AUTOSAR XML (schema 3.1.2)
package /Components/SWC_AdvMaxT
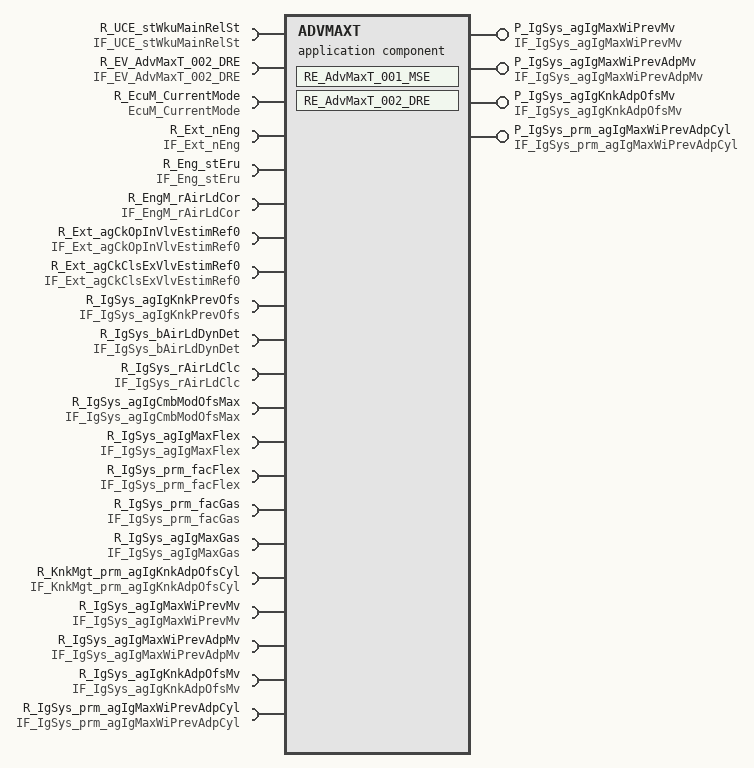
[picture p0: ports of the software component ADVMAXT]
  application software component type ADVMAXT  # AdvMaxT
    require port R_UCE_stWkuMainRelSt: required-interface=IF_UCE_stWkuMainRelSt
    4 x provide port:
      P_IgSys_agIgMaxWiPrevMv: unqueued-sender-com-spec{data-element=IgSys_agIgMaxWiPrevMv, can-invalidate=false, init-value=UInt8InitValue}, provided-interface=IF_IgSys_agIgMaxWiPrevMv
      P_IgSys_agIgMaxWiPrevAdpMv: unqueued-sender-com-spec{data-element=IgSys_agIgMaxWiPrevAdpMv, can-invalidate=false, init-value=ConstantValue}, provided-interface=IF_IgSys_agIgMaxWiPrevAdpMv
      P_IgSys_agIgKnkAdpOfsMv: unqueued-sender-com-spec{data-element=IgSys_agIgKnkAdpOfsMv, can-invalidate=false, init-value=UInt8InitValue1}, provided-interface=IF_IgSys_agIgKnkAdpOfsMv
      P_IgSys_prm_agIgMaxWiPrevAdpCyl: unqueued-sender-com-spec{data-element=IgSys_prm_agIgMaxWiPrevAdpCyl, can-invalidate=false, init-value=ArrayConstantValue}, provided-interface=IF_IgSys_prm_agIgMaxWiPrevAdpCyl
    20 x require port:
      R_EV_AdvMaxT_002_DRE: unqueued-receiver-com-spec{data-element=EV_AdvMaxT_002_DRE, init-value=UInt8InitValue3, resync-time=0}, required-interface=IF_EV_AdvMaxT_002_DRE
      R_EcuM_CurrentMode: required-interface=EcuM_CurrentMode
      R_Ext_nEng: unqueued-receiver-com-spec{data-element=Ext_nEng, init-value=ConstantValue5, resync-time=0}, required-interface=IF_Ext_nEng
      R_Eng_stEru: unqueued-receiver-com-spec{data-element=Eng_stEru, init-value=UInt8InitValue7, resync-time=0}, required-interface=IF_Eng_stEru
      R_EngM_rAirLdCor: unqueued-receiver-com-spec{data-element=EngM_rAirLdCor, init-value=ConstantValue9, resync-time=0}, required-interface=IF_EngM_rAirLdCor
      R_Ext_agCkOpInVlvEstimRef0: unqueued-receiver-com-spec{data-element=Ext_agCkOpInVlvEstimRef0, init-value=SInt16InitValue, resync-time=0}, required-interface=IF_Ext_agCkOpInVlvEstimRef0
      R_Ext_agCkClsExVlvEstimRef0: unqueued-receiver-com-spec{data-element=Ext_agCkClsExVlvEstimRef0, init-value=SInt16InitValue11, resync-time=0}, required-interface=IF_Ext_agCkClsExVlvEstimRef0
      R_IgSys_agIgKnkPrevOfs: unqueued-receiver-com-spec{data-element=IgSys_agIgKnkPrevOfs, init-value=UInt8InitValue13, resync-time=0}, required-interface=IF_IgSys_agIgKnkPrevOfs
      R_IgSys_bAirLdDynDet: unqueued-receiver-com-spec{data-element=IgSys_bAirLdDynDet, init-value=BooleanInitValue, resync-time=0}, required-interface=IF_IgSys_bAirLdDynDet
      R_IgSys_rAirLdClc: unqueued-receiver-com-spec{data-element=IgSys_rAirLdClc, init-value=UInt16InitValue, resync-time=0}, required-interface=IF_IgSys_rAirLdClc
      R_IgSys_agIgCmbModOfsMax: unqueued-receiver-com-spec{data-element=IgSys_agIgCmbModOfsMax, init-value=UInt8InitValue15, resync-time=0}, required-interface=IF_IgSys_agIgCmbModOfsMax
      R_IgSys_agIgMaxFlex: unqueued-receiver-com-spec{data-element=IgSys_agIgMaxFlex, init-value=UInt8InitValue17, resync-time=0}, required-interface=IF_IgSys_agIgMaxFlex
      R_IgSys_prm_facFlex: unqueued-receiver-com-spec{data-element=IgSys_prm_facFlex, init-value=rt_Array_UInt8_10InitValue, resync-time=0}, required-interface=IF_IgSys_prm_facFlex
      R_IgSys_prm_facGas: unqueued-receiver-com-spec{data-element=IgSys_prm_facGas, init-value=rt_Array_UInt8_10InitValue19, resync-time=0}, required-interface=IF_IgSys_prm_facGas
      R_IgSys_agIgMaxGas: unqueued-receiver-com-spec{data-element=IgSys_agIgMaxGas, init-value=UInt8InitValue21, resync-time=0}, required-interface=IF_IgSys_agIgMaxGas
      R_KnkMgt_prm_agIgKnkAdpOfsCyl: unqueued-receiver-com-spec{data-element=KnkMgt_prm_agIgKnkAdpOfsCyl, init-value=rt_Array_UInt8_6InitValue, resync-time=0}, required-interface=IF_KnkMgt_prm_agIgKnkAdpOfsCyl
      R_IgSys_agIgMaxWiPrevMv: unqueued-receiver-com-spec{data-element=IgSys_agIgMaxWiPrevMv, init-value=UInt8InitValue, resync-time=0}, required-interface=IF_IgSys_agIgMaxWiPrevMv
      R_IgSys_agIgMaxWiPrevAdpMv: unqueued-receiver-com-spec{data-element=IgSys_agIgMaxWiPrevAdpMv, init-value=ConstantValue, resync-time=0}, required-interface=IF_IgSys_agIgMaxWiPrevAdpMv
      R_IgSys_agIgKnkAdpOfsMv: unqueued-receiver-com-spec{data-element=IgSys_agIgKnkAdpOfsMv, init-value=UInt8InitValue23, resync-time=0}, required-interface=IF_IgSys_agIgKnkAdpOfsMv
      R_IgSys_prm_agIgMaxWiPrevAdpCyl: unqueued-receiver-com-spec{data-element=IgSys_prm_agIgMaxWiPrevAdpCyl, init-value=ArrayConstantValue, resync-time=0}, required-interface=IF_IgSys_prm_agIgMaxWiPrevAdpCyl
  20 x constant specification:
    ArrayConstantValue
      value:
        array specification ArrayConstantValue: type=rt_Array_UInt8_6_m2
          6 x integer literal, all with type=DT_IgSys_prm_agIgMaxWiPrevAdpCyl, value=255:
            Const
            Const{1..5}
    BooleanInitValue
      value:
        boolean literal BooleanInitValue: type=DT_IgSys_bAirLdDynDet, value=false
    ConstantValue
      value:
        integer literal ConstantValue: type=DT_IgSys_agIgMaxWiPrevAdpMv, value=255
    ConstantValue5
      value:
        integer literal ConstantValue5: type=DT_Ext_nEng, value=0
    ConstantValue9
      value:
        integer literal ConstantValue9: type=DT_EngM_rAirLdCor, value=0
    rt_Array_UInt8_10InitValue
      value:
        array specification rt_Array_UInt8_10InitValue: type=rt_Array_UInt8_10_m0
          10 x integer literal, all with type=DT_IgSys_prm_facFlex, value=0:
            UInt8_{1..10}
    rt_Array_UInt8_10InitValue19
      value:
        array specification rt_Array_UInt8_10InitValue19: type=rt_Array_UInt8_10_m1
          10 x integer literal, all with type=DT_IgSys_prm_facGas, value=0:
            UInt8_{1..10}
    rt_Array_UInt8_6InitValue
      value:
        array specification rt_Array_UInt8_6InitValue: type=rt_Array_UInt8_6_m5
          6 x integer literal, all with type=DT_KnkMgt_prm_agIgKnkAdpOfsCyl, value=0:
            UInt8_{1..6}
    SInt16InitValue
      value:
        integer literal SInt16InitValue: type=DT_Ext_agCkOpInVlvEstimRef0, value=-1024
    SInt16InitValue11
      value:
        integer literal SInt16InitValue11: type=DT_Ext_agCkClsExVlvEstimRef0, value=-1024
    UInt16InitValue
      value:
        integer literal UInt16InitValue: type=DT_IgSys_rAirLdClc, value=0
    UInt8InitValue
      value:
        integer literal UInt8InitValue: type=DT_IgSys_agIgMaxWiPrevMv, value=255
    UInt8InitValue1
      value:
        integer literal UInt8InitValue1: type=DT_IgSys_agIgKnkAdpOfsMv, value=96
    UInt8InitValue13
      value:
        integer literal UInt8InitValue13: type=DT_IgSys_agIgKnkPrevOfs, value=96
    UInt8InitValue15
      value:
        integer literal UInt8InitValue15: type=DT_IgSys_agIgCmbModOfsMax, value=96
    UInt8InitValue17
      value:
        integer literal UInt8InitValue17: type=DT_IgSys_agIgMaxFlex, value=96
    UInt8InitValue21
      value:
        integer literal UInt8InitValue21: type=DT_IgSys_agIgMaxGas, value=96
    UInt8InitValue23
      value:
        integer literal UInt8InitValue23: type=DT_IgSys_agIgKnkAdpOfsMv, value=96
    UInt8InitValue3
      value:
        integer literal UInt8InitValue3: type=DT_EV_AdvMaxT_002_DRE, value=0
    UInt8InitValue7
      value:
        integer literal UInt8InitValue7: type=DT_Eng_stEru, value=1
  internal behavior IB_AdvMaxT: component=ADVMAXT
    mode switch event EV_AdvMaxT_001_MSE: start-on-event=RE_AdvMaxT_001_MSE, activation=ENTRY, mode=R_EcuM_CurrentMode.currentMode.RUN
    data received event EV_AdvMaxT_002_DRE: mode-dependency=dependent-on-mode=[R_UCE_stWkuMainRelSt.RCD_stWkuMainRelSt.PreMainWakeUp, R_UCE_stWkuMainRelSt.RCD_stWkuMainRelSt.PostMainWakeUp, R_UCE_stWkuMainRelSt.RCD_stWkuMainRelSt.Invalid], start-on-event=RE_AdvMaxT_002_DRE, data=R_EV_AdvMaxT_002_DRE.EV_AdvMaxT_002_DRE
    runnable RE_AdvMaxT_001_MSE
      4 x data send point:
        ds_IgSys_agIgMaxWiPrevAdpMv: data-element=P_IgSys_agIgMaxWiPrevAdpMv.IgSys_agIgMaxWiPrevAdpMv
        ds_IgSys_prm_agIgMaxWiPrevAdpCyl: data-element=P_IgSys_prm_agIgMaxWiPrevAdpCyl.IgSys_prm_agIgMaxWiPrevAdpCyl
        ds_IgSys_agIgKnkAdpOfsMv: data-element=P_IgSys_agIgKnkAdpOfsMv.IgSys_agIgKnkAdpOfsMv
        ds_IgSys_agIgMaxWiPrevMv: data-element=P_IgSys_agIgMaxWiPrevMv.IgSys_agIgMaxWiPrevMv
    runnable RE_AdvMaxT_002_DRE
      19 x data receive point:
        dr_IgSys_agIgMaxGas: data-element=R_IgSys_agIgMaxGas.IgSys_agIgMaxGas
        dr_IgSys_rAirLdClc: data-element=R_IgSys_rAirLdClc.IgSys_rAirLdClc
        dr_IgSys_prm_agIgMaxWiPrevAdpCyl: data-element=R_IgSys_prm_agIgMaxWiPrevAdpCyl.IgSys_prm_agIgMaxWiPrevAdpCyl
        dr_IgSys_prm_facFlex: data-element=R_IgSys_prm_facFlex.IgSys_prm_facFlex
        dr_IgSys_agIgCmbModOfsMax: data-element=R_IgSys_agIgCmbModOfsMax.IgSys_agIgCmbModOfsMax
        dr_IgSys_prm_facGas: data-element=R_IgSys_prm_facGas.IgSys_prm_facGas
        dr_Eng_stEru: data-element=R_Eng_stEru.Eng_stEru
        dr_IgSys_agIgMaxFlex: data-element=R_IgSys_agIgMaxFlex.IgSys_agIgMaxFlex
        dr_KnkMgt_prm_agIgKnkAdpOfsCyl: data-element=R_KnkMgt_prm_agIgKnkAdpOfsCyl.KnkMgt_prm_agIgKnkAdpOfsCyl
        dr_Ext_agCkOpInVlvEstimRef0: data-element=R_Ext_agCkOpInVlvEstimRef0.Ext_agCkOpInVlvEstimRef0
        dr_IgSys_agIgMaxWiPrevMv: data-element=R_IgSys_agIgMaxWiPrevMv.IgSys_agIgMaxWiPrevMv
        dr_IgSys_agIgMaxWiPrevAdpMv: data-element=R_IgSys_agIgMaxWiPrevAdpMv.IgSys_agIgMaxWiPrevAdpMv
        dr_IgSys_agIgKnkPrevOfs: data-element=R_IgSys_agIgKnkPrevOfs.IgSys_agIgKnkPrevOfs
        dr_EngM_rAirLdCor: data-element=R_EngM_rAirLdCor.EngM_rAirLdCor
        dr_Ext_nEng: data-element=R_Ext_nEng.Ext_nEng
        dr_IgSys_agIgKnkAdpOfsMv: data-element=R_IgSys_agIgKnkAdpOfsMv.IgSys_agIgKnkAdpOfsMv
        dr_Ext_agCkClsExVlvEstimRef0: data-element=R_Ext_agCkClsExVlvEstimRef0.Ext_agCkClsExVlvEstimRef0
        dr_IgSys_bAirLdDynDet: data-element=R_IgSys_bAirLdDynDet.IgSys_bAirLdDynDet
        dr_EV_AdvMaxT_002_DRE: data-element=R_EV_AdvMaxT_002_DRE.EV_AdvMaxT_002_DRE
      data send point ds_IgSys_agIgKnkAdpOfsMv: data-element=P_IgSys_agIgKnkAdpOfsMv.IgSys_agIgKnkAdpOfsMv
      data send point ds_IgSys_agIgMaxWiPrevMv: data-element=P_IgSys_agIgMaxWiPrevMv.IgSys_agIgMaxWiPrevMv
  swc implementation Imp_AdvMaxT: code-generator=Real-Time Workshop Embedded Coder 5.5 (R2010a) 25-Jan-2010, programming-language=C, behavior=IB_AdvMaxT
    code-descriptors:
      code CodeDescriptor: type=SRC
        10 x xfile:
          AdvMaxT_types_h: url=AdvMaxT_types.h
          AdvMaxT_MemMap_h: url=AdvMaxT_MemMap.h
          AdvMaxT_Version_c: url=AdvMaxT_Version.c
          AdvMaxT_Def_c: url=AdvMaxT_Def.c
          AdvMaxT_data_c: url=AdvMaxT_data.c
          AdvMaxT_h: url=AdvMaxT.h
          AdvMaxT_import_h: url=AdvMaxT_import.h
          AdvMaxT_private_h: url=AdvMaxT_private.h
          AdvMaxT_c: url=AdvMaxT.c
          AdvMaxT_Version_h: url=AdvMaxT_Version.h
